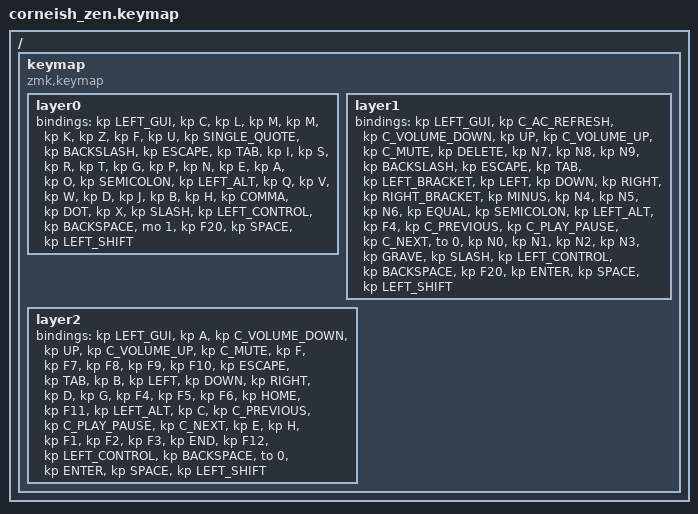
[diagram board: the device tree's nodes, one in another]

  /*
  * Copyright (c) 2020 The ZMK Contributors
  *
  * SPDX-License-Identifier: MIT
  */

  #include <behaviors.dtsi>
  #include <dt-bindings/zmk/keys.h>
  #include <dt-bindings/zmk/bt.h>
  #include <dt-bindings/zmk/ext_power.h>

  / {
    keymap {
      compatible = "zmk,keymap";
  layer0 {
          bindings = <
          &kp LEFT_GUI &kp C &kp L &kp M &kp M &kp K &kp Z &kp F &kp U &kp SINGLE_QUOTE &kp BACKSLASH &kp ESCAPE &kp TAB &kp I &kp S &kp R &kp T &kp G &kp P &kp N &kp E &kp A &kp O &kp SEMICOLON &kp LEFT_ALT &kp Q &kp V &kp W &kp D &kp J &kp B &kp H &kp COMMA &kp DOT &kp X &kp SLASH &kp LEFT_CONTROL &kp BACKSPACE &mo 1 &kp F20 &kp SPACE &kp LEFT_SHIFT
          >;
        };layer1 {
          bindings = <
          &kp LEFT_GUI &kp C_AC_REFRESH &kp C_VOLUME_DOWN &kp UP &kp C_VOLUME_UP &kp C_MUTE &kp DELETE &kp N7 &kp N8 &kp N9 &kp BACKSLASH &kp ESCAPE &kp TAB &kp LEFT_BRACKET &kp LEFT &kp DOWN &kp RIGHT &kp RIGHT_BRACKET &kp MINUS &kp N4 &kp N5 &kp N6 &kp EQUAL &kp SEMICOLON &kp LEFT_ALT &kp F4 &kp C_PREVIOUS &kp C_PLAY_PAUSE &kp C_NEXT &to 0 &kp N0 &kp N1 &kp N2 &kp N3 &kp GRAVE &kp SLASH &kp LEFT_CONTROL &kp BACKSPACE &kp F20 &kp ENTER &kp SPACE &kp LEFT_SHIFT
          >;
        };layer2 {
          bindings = <
          &kp LEFT_GUI &kp A &kp C_VOLUME_DOWN &kp UP &kp C_VOLUME_UP &kp C_MUTE &kp F &kp F7 &kp F8 &kp F9 &kp F10 &kp ESCAPE &kp TAB &kp B &kp LEFT &kp DOWN &kp RIGHT &kp D &kp G &kp F4 &kp F5 &kp F6 &kp HOME &kp F11 &kp LEFT_ALT &kp C &kp C_PREVIOUS &kp C_PLAY_PAUSE &kp C_NEXT &kp E &kp H &kp F1 &kp F2 &kp F3 &kp END &kp F12 &kp LEFT_CONTROL &kp BACKSPACE &to 0 &kp ENTER &kp SPACE &kp LEFT_SHIFT
          >;
        };
    };
  };
 
